# MB9BF61xS register map
File version: 1.7
CPU: 
Registers are 32-bit, read-write, reset 0x0 unless marked. A register's access mark holds for its fields unless they carry their own. Offsets are from the block's base; lines under a group give offsets from that group; [hi:lo] are bit positions; {n}, {i} and the like mark numbered series; 'fields as' and 'values as' point back to an identical list; <NAME> marks a mode.

## Memory map
0x40000000 FLASH_IF size 0xC — Flash Memory
0x40010000 CRG size 0x1 — Clock Unit Registers
0x40011000 HWWDT size 0x4 — Hardware Watchdog Timer
0x40012000 SWWDT size 0x4 — Software Watchdog Timer
0x40015000 DTIM size 0x1C — Dual Timer
0x40020000 MFT0 size 0x2 — Multifunction Timer 0
0x40021000 MFT1 size 0x2 — Multifunction Timer 0
0x40022000 MFT2 size 0x2 — Multifunction Timer 0
0x40024000 MFT_PPG size 0x2 — PPG Configuration
0x40025000 BT0 size 0x2 — Base Timer 0
0x40025040 BT1 size 0x2 — Base Timer 0
0x40025080 BT2 size 0x2 — Base Timer 0
0x400250C0 BT3 size 0x2 — Base Timer 0
0x40025100 BTIOSEL03 size 0x2 — Base Timer I/O Select
0x40025200 BT4 size 0x2 — Base Timer 0
0x40025240 BT5 size 0x2 — Base Timer 0
0x40025280 BT6 size 0x2 — Base Timer 0
0x400252C0 BT7 size 0x2 — Base Timer 0
0x40025300 BTIOSEL47 size 0x2 — Base Timer I/O Select
0x40025400 BT8 size 0x2 — Base Timer 0
0x40025440 BT9 size 0x2 — Base Timer 0
0x40025480 BT10 size 0x2 — Base Timer 0
0x400254C0 BT11 size 0x2 — Base Timer 0
0x40025500 BTIOSEL8B size 0x2 — Base Timer I/O Select
0x40025600 BT12 size 0x2 — Base Timer 0
0x40025640 BT13 size 0x2 — Base Timer 0
0x40025680 BT14 size 0x2 — Base Timer 0
0x400256C0 BT15 size 0x2 — Base Timer 0
0x40025700 BTIOSELCF size 0x2 — Base Timer I/O Select
0x40025F00 SBSSR blocks up to offset 0xFE — Software-based Simultaneous Startup Register
0x40026000 QPRC0 size 0x2 — Quadrature Position/Revolution Counter 0
0x40026040 QPRC1 size 0x2 — Quadrature Position/Revolution Counter 0
0x40026080 QPRC2 size 0x2 — Quadrature Position/Revolution Counter 0
0x40027000 ADC0 size 0x2 — ADC0 Registers
0x40027100 ADC1 size 0x2 — ADC0 Registers
0x40027200 ADC2 size 0x2 — ADC0 Registers
0x4002E000 CRTRIM size 0x1 — CR Trimming Registers
0x40030000 EXTI size 0x4 — External Interrupt and NMI Control
0x40031000 INTREQ size 0x4 — Interrupts
0x40033000 GPIO size 0x740 — General-purpose I/O ports
0x40035000 LVD size 0x1 — Low-voltage Detection
0x40036000 USBETHERCLK size 0x1 — USB/Ethernet Clock
0x40038000 MFS0 size 0x2 — Multi-function Serial Interface 0
0x40038100 MFS1 size 0x2 — Multi-function Serial Interface 0
0x40038200 MFS2 size 0x2 — Multi-function Serial Interface 0
0x40038300 MFS3 size 0x2 — Multi-function Serial Interface 0
0x40038400 MFS4 size 0x2 — Multi-function Serial Interface 4
0x40038500 MFS5 size 0x2 — Multi-function Serial Interface 4
0x40038600 MFS6 size 0x2 — Multi-function Serial Interface 4
0x40038700 MFS7 size 0x2 — Multi-function Serial Interface 4
0x40038800 MFS_NFC size 0x2 — I2C Auxiliary Noise Filter Setting Register
0x40039000 CRC size 0x1 — CRC Registers
0x4003A000 WC size 0x3 — Watch Counter
0x4003F000 EXBUS size 0x80 — External Bus Interface
0x40040000 USB0 blocks up to offset 0x2102 — USB0 Function
0x40050000 USB1 blocks up to offset 0x2102 — USB0 Function
0x40060000 DMAC size 0x4 — DMAC Registers
0x40064000 ETHERNET_MAC0 size 0x1058
0x40066000 ETHERNET_CONTROL size 0x4 — Ethernet system control
0x40067000 ETHERNET_MAC1 size 0x1058 — Ethernet-MAC 0

## Interrupts
0 CSV (CRG)
1 SWDT (SWWDT)
2 LVD
3 WFG (MFT{n} (n=0..2))
4 EXTINT0_7 (EXTI)
5 EXTINT8_31 (EXTI)
6 DTIM_QDU (DTIM)
{2n+7} MFS{n}RX (MFS{n}) (n=0..7)
{2n+8} MFS{n}TX (MFS{n}) (n=0..7)
23 PPG (MFT_PPG)
24 OSC_PLL_WC (CRG)
25 ADC0
26 ADC1
27 ADC2
28 FRTIM (MFT{n} (n=0..2))
29 INCAP (MFT{n} (n=0..2))
30 OUTCOMP (MFT{n} (n=0..2))
31 BTIM0_7 (BT{n} (n=0..15))
32 ETHER_MAC0 (ETHERNET_MAC0)
33 ETHER_MAC1 (ETHERNET_MAC1)
34 USB0F (USB0)
35 USB0F_USB0H (USB0)
36 USB1F (USB1)
37 USB1F_USB1H (USB1)
{n+38} DMAC{n} (DMAC) (n=0..7)

## FLASH_IF — Flash Memory
Base 0x40000000
0x00 FASZR reset 0x2 — Flash Access Size Register
  [1:0] ASZ — Flash Access Size
0x04 FRWTR reset 0x2 — Flash Read Wait Register
  [1:0] RWT — Read Wait Cycle
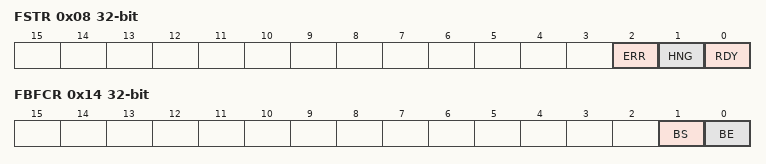
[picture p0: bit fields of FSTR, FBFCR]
0x08 FSTR ro — Flash Status Register
  [2] ERR rw — Flash ECC Error
  [1] HNG — Flash Hang flag
  [0] RDY — Flash Rdy
0x10 FSYNDN — Flash Sync Down Register
  [2:0] SD — Flash Sync
0x14 FBFCR — Flash Buffer Control Register
  [1] BS ro — Buffer Status
  [0] BE — Buffer Enable
0x100 CRTRMM ro reset not defined — CR Trimming Data Mirror Register
  [9:0] TRMM — CR Trimming Data Mirror
